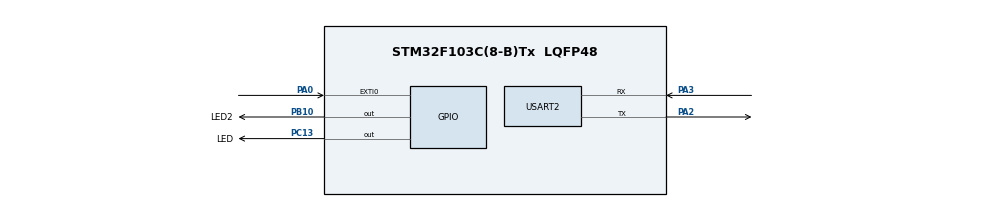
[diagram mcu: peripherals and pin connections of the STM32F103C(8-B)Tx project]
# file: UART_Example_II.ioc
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Dma.Request0=USART2_RX
Dma.USART2_RX.0.Direction=DMA_PERIPH_TO_MEMORY
Dma.USART2_RX.0.Instance=DMA1_Channel6
Dma.USART2_RX.0.MemDataAlignment=DMA_MDATAALIGN_BYTE
Dma.USART2_RX.0.MemInc=DMA_MINC_ENABLE
Dma.USART2_RX.0.Mode=DMA_NORMAL
Dma.USART2_RX.0.PeriphDataAlignment=DMA_PDATAALIGN_BYTE
Dma.USART2_RX.0.PeriphInc=DMA_PINC_DISABLE
Dma.USART2_RX.0.Priority=DMA_PRIORITY_LOW
Mcu.Family=STM32F1
Mcu.Name=STM32F103C(8-B)Tx
Mcu.Package=LQFP48
NVIC.DMA1_Channel6_IRQn=true\:0\:0\:false\:false\:true\:false
NVIC.EXTI0_IRQn=true\:0\:0\:false\:false\:true\:true
NVIC.PriorityGroup=NVIC_PRIORITYGROUP_4
PA0-WKUP.GPIO_PuPd=GPIO_PULLUP
PA0-WKUP.Signal=GPXTI0
PA13.Mode=Serial_Wire
PA13.Signal=SYS_JTMS-SWDIO
PA14.Mode=Serial_Wire
PA14.Signal=SYS_JTCK-SWCLK
PA2.Mode=Asynchronous
PA2.Signal=USART2_TX
PA3.Mode=Asynchronous
PA3.Signal=USART2_RX
PB10.GPIO_Label=LED2
PB10.Signal=GPIO_Output
PC13-TAMPER-RTC.GPIO_Label=LED
PC13-TAMPER-RTC.Signal=GPIO_Output
ProjectManager.HeapSize=0x200
ProjectManager.StackSize=0x400
ProjectManager.TargetToolchain=TrueSTUDIO
RCC.APB1Freq_Value=8000000
RCC.APB2Freq_Value=8000000
TIM3.Prescaler=8000
USART2.VirtualMode=VM_ASYNC
VP_TIM3_VS_ClockSourceINT.Mode=Internal
board=custom

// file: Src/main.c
/* USER CODE BEGIN Header */
/**
  ******************************************************************************
  * @file           : main.c
  * @brief          : Main program body
  ******************************************************************************
  ** This notice applies to any and all portions of this file
  * that are not between comment pairs USER CODE BEGIN and
  * USER CODE END. Other portions of this file, whether
  * inserted by the user or by software development tools
  * are owned by their respective copyright owners.
  *
  * COPYRIGHT(c) 2019 STMicroelectronics
  *
  * Redistribution and use in source and binary forms, with or without modification,
  * are permitted provided that the following conditions are met:
  *   1. Redistributions of source code must retain the above copyright notice,
  *      this list of conditions and the following disclaimer.
  *   2. Redistributions in binary form must reproduce the above copyright notice,
  *      this list of conditions and the following disclaimer in the documentation
  *      and/or other materials provided with the distribution.
  *   3. Neither the name of STMicroelectronics nor the names of its contributors
  *      may be used to endorse or promote products derived from this software
  *      without specific prior written permission.
  *
  * THIS SOFTWARE IS PROVIDED BY THE COPYRIGHT HOLDERS AND CONTRIBUTORS "AS IS"
  * AND ANY EXPRESS OR IMPLIED WARRANTIES, INCLUDING, BUT NOT LIMITED TO, THE
  * IMPLIED WARRANTIES OF MERCHANTABILITY AND FITNESS FOR A PARTICULAR PURPOSE ARE
  * DISCLAIMED. IN NO EVENT SHALL THE COPYRIGHT HOLDER OR CONTRIBUTORS BE LIABLE
  * FOR ANY DIRECT, INDIRECT, INCIDENTAL, SPECIAL, EXEMPLARY, OR CONSEQUENTIAL
  * DAMAGES (INCLUDING, BUT NOT LIMITED TO, PROCUREMENT OF SUBSTITUTE GOODS OR
  * SERVICES; LOSS OF USE, DATA, OR PROFITS; OR BUSINESS INTERRUPTION) HOWEVER
  * CAUSED AND ON ANY THEORY OF LIABILITY, WHETHER IN CONTRACT, STRICT LIABILITY,
  * OR TORT (INCLUDING NEGLIGENCE OR OTHERWISE) ARISING IN ANY WAY OUT OF THE USE
  * OF THIS SOFTWARE, EVEN IF ADVISED OF THE POSSIBILITY OF SUCH DAMAGE.
  *
  ******************************************************************************
  */
/* USER CODE END Header */

#include "main.h"

/* USER CODE BEGIN Includes */
#include <string.h>

/* USER CODE END Includes */

TIM_HandleTypeDef htim3;

UART_HandleTypeDef huart2;
DMA_HandleTypeDef hdma_usart2_rx;

void SystemClock_Config(void);
static void MX_GPIO_Init(void);
static void MX_DMA_Init(void);
static void MX_TIM3_Init(void);
static void MX_USART2_UART_Init(void);

int main(void)
{

  /* MCU Configuration--------------------------------------------------------*/

  /* Reset of all peripherals, Initializes the Flash interface and the Systick. */
  HAL_Init();

  /* Configure the system clock */
  SystemClock_Config();

  /* Initialize all configured peripherals */
  MX_GPIO_Init();
  MX_DMA_Init();
  MX_TIM3_Init();
  MX_USART2_UART_Init();
  /* USER CODE BEGIN 2 */
  char txData[30] = "Hello World";
  char rxData[11];
  HAL_UART_Receive_DMA(&huart2, (uint8_t *)rxData, 10);
  /* USER CODE END 2 */

  /* Infinite loop */
  while (1)
  {
	HAL_UART_Transmit(&huart2, (uint8_t *)txData, strlen(txData), 10);

	HAL_GPIO_TogglePin(LED_GPIO_Port, LED_Pin);
	HAL_Delay(300);

  }
}

void SystemClock_Config(void)
{
  RCC_OscInitTypeDef RCC_OscInitStruct = {0};
  RCC_ClkInitTypeDef RCC_ClkInitStruct = {0};

  /**Initializes the CPU, AHB and APB busses clocks
  */
  RCC_OscInitStruct.OscillatorType = RCC_OSCILLATORTYPE_HSI;
  RCC_OscInitStruct.HSIState = RCC_HSI_ON;
  RCC_OscInitStruct.HSICalibrationValue = RCC_HSICALIBRATION_DEFAULT;
  RCC_OscInitStruct.PLL.PLLState = RCC_PLL_NONE;
  if (HAL_RCC_OscConfig(&RCC_OscInitStruct) != HAL_OK)
  {
    Error_Handler();
  }
  /**Initializes the CPU, AHB and APB busses clocks
  */
  RCC_ClkInitStruct.ClockType = RCC_CLOCKTYPE_HCLK|RCC_CLOCKTYPE_SYSCLK
                              |RCC_CLOCKTYPE_PCLK1|RCC_CLOCKTYPE_PCLK2;
  RCC_ClkInitStruct.SYSCLKSource = RCC_SYSCLKSOURCE_HSI;
  RCC_ClkInitStruct.AHBCLKDivider = RCC_SYSCLK_DIV1;
  RCC_ClkInitStruct.APB1CLKDivider = RCC_HCLK_DIV1;
  RCC_ClkInitStruct.APB2CLKDivider = RCC_HCLK_DIV1;

  if (HAL_RCC_ClockConfig(&RCC_ClkInitStruct, FLASH_LATENCY_0) != HAL_OK)
  {
    Error_Handler();
  }
}

static void MX_TIM3_Init(void)
{

  TIM_ClockConfigTypeDef sClockSourceConfig = {0};
  TIM_MasterConfigTypeDef sMasterConfig = {0};

  htim3.Instance = TIM3;
  htim3.Init.Prescaler = 8000;
  htim3.Init.CounterMode = TIM_COUNTERMODE_UP;
  htim3.Init.Period = 1000;
  htim3.Init.ClockDivision = TIM_CLOCKDIVISION_DIV1;
  htim3.Init.AutoReloadPreload = TIM_AUTORELOAD_PRELOAD_DISABLE;
  if (HAL_TIM_Base_Init(&htim3) != HAL_OK)
  {
    Error_Handler();
  }
  sClockSourceConfig.ClockSource = TIM_CLOCKSOURCE_INTERNAL;
  if (HAL_TIM_ConfigClockSource(&htim3, &sClockSourceConfig) != HAL_OK)
  {
    Error_Handler();
  }
  sMasterConfig.MasterOutputTrigger = TIM_TRGO_RESET;
  sMasterConfig.MasterSlaveMode = TIM_MASTERSLAVEMODE_DISABLE;
  if (HAL_TIMEx_MasterConfigSynchronization(&htim3, &sMasterConfig) != HAL_OK)
  {
    Error_Handler();
  }

}

static void MX_USART2_UART_Init(void)
{

  huart2.Instance = USART2;
  huart2.Init.BaudRate = 115200;
  huart2.Init.WordLength = UART_WORDLENGTH_8B;
  huart2.Init.StopBits = UART_STOPBITS_1;
  huart2.Init.Parity = UART_PARITY_NONE;
  huart2.Init.Mode = UART_MODE_TX_RX;
  huart2.Init.HwFlowCtl = UART_HWCONTROL_NONE;
  huart2.Init.OverSampling = UART_OVERSAMPLING_16;
  if (HAL_UART_Init(&huart2) != HAL_OK)
  {
    Error_Handler();
  }

}

static void MX_DMA_Init(void)
{
  /* DMA controller clock enable */
  __HAL_RCC_DMA1_CLK_ENABLE();

  /* DMA interrupt init */
  /* DMA1_Channel6_IRQn interrupt configuration */
  HAL_NVIC_SetPriority(DMA1_Channel6_IRQn, 0, 0);
  HAL_NVIC_EnableIRQ(DMA1_Channel6_IRQn);

}

static void MX_GPIO_Init(void)
{
  GPIO_InitTypeDef GPIO_InitStruct = {0};

  /* GPIO Ports Clock Enable */
  __HAL_RCC_GPIOC_CLK_ENABLE();
  __HAL_RCC_GPIOA_CLK_ENABLE();
  __HAL_RCC_GPIOB_CLK_ENABLE();

  /*Configure GPIO pin Output Level */
  HAL_GPIO_WritePin(LED_GPIO_Port, LED_Pin, GPIO_PIN_RESET);

  /*Configure GPIO pin Output Level */
  HAL_GPIO_WritePin(LED2_GPIO_Port, LED2_Pin, GPIO_PIN_RESET);

  /*Configure GPIO pin : LED_Pin */
  GPIO_InitStruct.Pin = LED_Pin;
  GPIO_InitStruct.Mode = GPIO_MODE_OUTPUT_PP;
  GPIO_InitStruct.Pull = GPIO_NOPULL;
  GPIO_InitStruct.Speed = GPIO_SPEED_FREQ_LOW;
  HAL_GPIO_Init(LED_GPIO_Port, &GPIO_InitStruct);

  /*Configure GPIO pin : PA0 */
  GPIO_InitStruct.Pin = GPIO_PIN_0;
  GPIO_InitStruct.Mode = GPIO_MODE_IT_RISING;
  GPIO_InitStruct.Pull = GPIO_PULLUP;
  HAL_GPIO_Init(GPIOA, &GPIO_InitStruct);

  /*Configure GPIO pin : LED2_Pin */
  GPIO_InitStruct.Pin = LED2_Pin;
  GPIO_InitStruct.Mode = GPIO_MODE_OUTPUT_PP;
  GPIO_InitStruct.Pull = GPIO_NOPULL;
  GPIO_InitStruct.Speed = GPIO_SPEED_FREQ_LOW;
  HAL_GPIO_Init(LED2_GPIO_Port, &GPIO_InitStruct);

  /* EXTI interrupt init*/
  HAL_NVIC_SetPriority(EXTI0_IRQn, 0, 0);
  HAL_NVIC_EnableIRQ(EXTI0_IRQn);

}

/* USER CODE BEGIN 4 */
void HAL_UART_RxCpltCallback(UART_HandleTypeDef *huart)
{
  /* Prevent unused argument(s) compilation warning */
  UNUSED(huart);
  /* NOTE: This function Should not be modified, when the callback is needed,
           the HAL_UART_RxCpltCallback could be implemented in the user file
   */
  HAL_GPIO_TogglePin(LED2_GPIO_Port, LED2_Pin);
}

/* USER CODE END 4 */

void Error_Handler(void)
{
}

/************************ (C) COPYRIGHT STMicroelectronics *****END OF FILE****/
